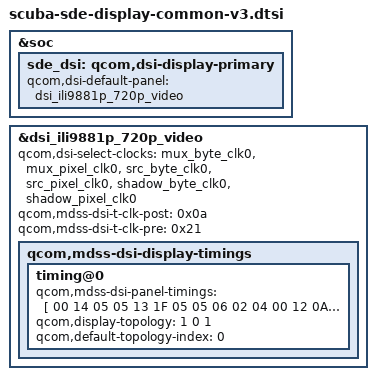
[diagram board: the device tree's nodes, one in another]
#include "dsi-panel-ili9881p-720-video.dtsi"

&soc {
	sde_dsi: qcom,dsi-display-primary {
		qcom,dsi-default-panel = <&dsi_ili9881p_720p_video>;
	};
};

&dsi_ili9881p_720p_video {
	qcom,dsi-select-clocks = "mux_byte_clk0", "mux_pixel_clk0",
		"src_byte_clk0", "src_pixel_clk0",
		"shadow_byte_clk0", "shadow_pixel_clk0";
	qcom,mdss-dsi-t-clk-post = <0x0a>;
	qcom,mdss-dsi-t-clk-pre = <0x21>;
	qcom,mdss-dsi-display-timings {
		timing@0 {
			qcom,mdss-dsi-panel-timings = [
				00 14 05 05 13 1F 05
				05 06 02 04 00 12 0A
			];
			qcom,display-topology = <1 0 1>;
			qcom,default-topology-index = <0>;
		};
	};
};
